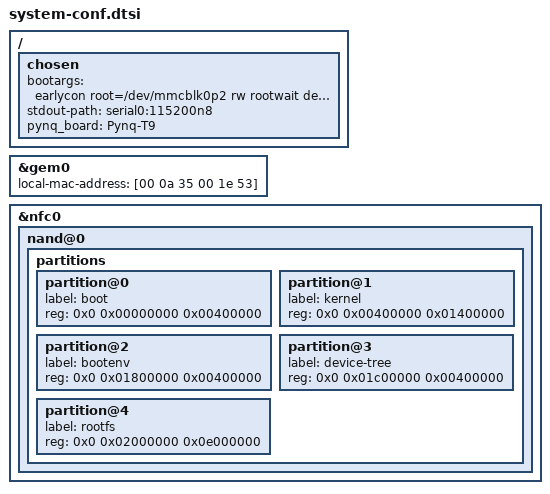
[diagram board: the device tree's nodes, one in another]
/*
 * CAUTION: This file is automatically generated by PetaLinux SDK.
 * DO NOT modify this file
 */


/ {
	chosen {
		bootargs = "earlycon root=/dev/mmcblk0p2 rw rootwait devtmpfs.mount=1 uio_pdrv_genirq.of_id=\"generic-uio\" clk_ignore_unused";
		stdout-path = "serial0:115200n8";
		pynq_board = "Pynq-T9";
	};
};

&gem0 {
	local-mac-address = [00 0a 35 00 1e 53];
};

&nfc0 {
	status = "okay";
	nand@0 {
		partitions {
			partition@0 { //4MB
				label = "boot";
				reg = <0x0 0x00000000 0x00400000>;
			};
			partition@1 { //20MB
				label = "kernel";
				reg = <0x0 0x00400000 0x01400000>;
			};
			partition@2 { //4MB
				label = "bootenv";
				reg = <0x0 0x01800000 0x00400000>;
			};
			partition@3 { //4MB
				label = "device-tree";
				reg = <0x0 0x01c00000 0x00400000>;
			};
			partition@4 { //192MB
				label = "rootfs";
				reg = <0x0 0x02000000 0x0e000000>;
			};
		};
	};
};

